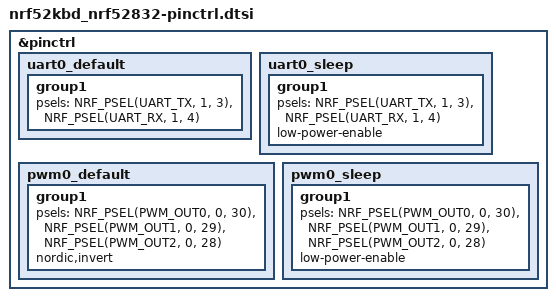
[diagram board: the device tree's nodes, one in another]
/*
 * Copyright (c) 2022 Nordic Semiconductor ASA
 *
 * SPDX-License-Identifier: LicenseRef-Nordic-5-Clause
 */

&pinctrl {
	uart0_default: uart0_default {
		group1 {
			psels = <NRF_PSEL(UART_TX, 1, 3)>,
				<NRF_PSEL(UART_RX, 1, 4)>;
		};
	};

	uart0_sleep: uart0_sleep {
		group1 {
			psels = <NRF_PSEL(UART_TX, 1, 3)>,
				<NRF_PSEL(UART_RX, 1, 4)>;
			low-power-enable;
		};
	};

	pwm0_default: pwm0_default {
		group1 {
			psels = <NRF_PSEL(PWM_OUT0, 0, 30)>,
				<NRF_PSEL(PWM_OUT1, 0, 29)>,
				<NRF_PSEL(PWM_OUT2, 0, 28)>;
			nordic,invert;
		};
	};

	pwm0_sleep: pwm0_sleep {
		group1 {
			psels = <NRF_PSEL(PWM_OUT0, 0, 30)>,
				<NRF_PSEL(PWM_OUT1, 0, 29)>,
				<NRF_PSEL(PWM_OUT2, 0, 28)>;
			low-power-enable;
		};
	};

};
